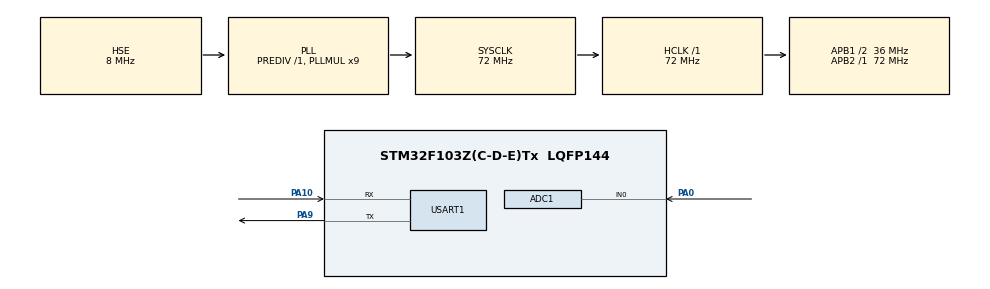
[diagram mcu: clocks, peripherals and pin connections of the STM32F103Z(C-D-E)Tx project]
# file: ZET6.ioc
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ADC1.Channel-0\#ChannelRegularConversion=ADC_CHANNEL_0
ADC1.ContinuousConvMode=DISABLE
ADC1.NbrOfConversionFlag=1
ADC1.Rank-0\#ChannelRegularConversion=1
ADC1.SamplingTime-0\#ChannelRegularConversion=ADC_SAMPLETIME_239CYCLES_5
ADC1.master=1
Mcu.Family=STM32F1
Mcu.Name=STM32F103Z(C-D-E)Tx
Mcu.Package=LQFP144
NVIC.PriorityGroup=NVIC_PRIORITYGROUP_4
OSC_IN.Mode=HSE-External-Oscillator
OSC_IN.Signal=RCC_OSC_IN
OSC_OUT.Mode=HSE-External-Oscillator
OSC_OUT.Signal=RCC_OSC_OUT
PA0-WKUP.Signal=ADCx_IN0
PA10.Mode=Asynchronous
PA10.Signal=USART1_RX
PA13.Signal=SYS_JTMS-SWDIO
PA14.Signal=SYS_JTCK-SWCLK
PA9.Mode=Asynchronous
PA9.Signal=USART1_TX
ProjectManager.HeapSize=0x200
ProjectManager.StackSize=0x400
ProjectManager.TargetToolchain=MDK-ARM V5.27
RCC.ADCPresc=RCC_ADCPCLK2_DIV8
RCC.AHBFreq_Value=72000000
RCC.APB1CLKDivider=RCC_HCLK_DIV2
RCC.APB1Freq_Value=36000000
RCC.APB1TimFreq_Value=72000000
RCC.APB2Freq_Value=72000000
RCC.APB2TimFreq_Value=72000000
RCC.HCLKFreq_Value=72000000
RCC.PLLMUL=RCC_PLL_MUL9
RCC.PLLSourceVirtual=RCC_PLLSOURCE_HSE
RCC.SYSCLKFreq_VALUE=72000000
RCC.SYSCLKSource=RCC_SYSCLKSOURCE_PLLCLK
RCC.USBFreq_Value=72000000
SH.ADCx_IN0.0=ADC1_IN0,IN0
USART1.VirtualMode=VM_ASYNC
VP_SYS_VS_ND.Mode=No_Debug
board=custom

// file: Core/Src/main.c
/* USER CODE BEGIN Header */
/**
  ******************************************************************************
  * @file           : main.c
  * @brief          : Main program body
  ******************************************************************************
  * @attention
  *
  * <h2><center>&copy; Copyright (c) 2021 STMicroelectronics.
  * All rights reserved.</center></h2>
  *
  * This software component is licensed by ST under BSD 3-Clause license,
  * the "License"; You may not use this file except in compliance with the
  * License. You may obtain a copy of the License at:
  *                        opensource.org/licenses/BSD-3-Clause
  *
  ******************************************************************************
  */
/* USER CODE END Header */
#include "main.h"
#include "debug.h"

ADC_HandleTypeDef hadc1;

UART_HandleTypeDef huart1;

void SystemClock_Config(void);
static void MX_GPIO_Init(void);
static void MX_ADC1_Init(void);
static void MX_USART1_UART_Init(void);

/* USER CODE BEGIN 0 */

uint16_t Get_Adc1_val()               //ADC获取
{
    HAL_ADC_Start(&hadc1);

    HAL_ADC_PollForConversion(&hadc1, 100);

    if(HAL_IS_BIT_SET(HAL_ADC_GetState(&hadc1), HAL_ADC_STATE_REG_EOC))
    {
        return HAL_ADC_GetValue(&hadc1);
    }
    return 0;
}

uint16_t Get_Adc1_Average()          //50ms数据融合
{
	uint8_t i,j = 0;
	uint16_t buf[10];
	uint16_t tempval = 0;

	for(i=0;i<10;i++)
	{
		buf[i] = Get_Adc1_val();
		HAL_Delay(5);
	}

	for(i=0;i<9;i++)                 //冒泡排序
	{
		for(j=0;j<9-i;j++)
		{
			if(buf[j]>buf[j+1])
			{
				tempval = buf[j];
				buf[j] = buf[j+1];
				buf[j+1] = tempval;
			}
		}
	}

	tempval = 0;
	for(i=1;i<9;i++)
	{
		tempval += buf[i];
	}

	return tempval/8;
}

uint16_t Get_Array_Max(uint16_t *data,uint8_t num)
{
	int max = 0;
	int i = 0;

	for(i=0;i<num;i++)
	{
		if(max < data[i])
		{
			max = data[i];
		}
	}

	return max;
}

uint16_t Get_Array_Min(uint16_t *data,uint8_t num)
{
	int min = 999;
	int i = 0;

	for(i=0;i<num;i++)
	{
		if(min > data[i])
		{
			min = data[i];
		}
	}

	return min;
}

/* USER CODE END 0 */

int main(void)
{
    /* USER CODE BEGIN 1 */

    uint16_t adcval,count = 0;
	uint16_t temp,max,min,mid,stateindex = 0;
	uint16_t time1,time2,BPM = 0;
	uint16_t data[50] = {0};

	uint16_t preReadData,readData = 0;
	uint16_t filter = 200;
	uint8_t index = 0;

	uint8_t Pre_State,Now_State = 0;

    /* USER CODE END 1 */

    /* MCU Configuration--------------------------------------------------------*/

    /* Reset of all peripherals, Initializes the Flash interface and the Systick. */
    HAL_Init();

    /* Configure the system clock */
    SystemClock_Config();

    /* Initialize all configured peripherals */
    MX_GPIO_Init();
    MX_ADC1_Init();
    MX_USART1_UART_Init();

    /* Infinite loop */
    /* USER CODE BEGIN WHILE */
    while(1)
    {

		preReadData = readData;
		temp = Get_Adc1_Average()-1500;
		if(temp < 1000)
		{
			readData = temp;
		}
//		if((readData-preReadData) < filter)    //滤除突变噪声信号
//		{
			data[index++] = readData;
//		}

		if(index >= 20)
		{
			index = 0;

			max = Get_Array_Max(data,20);
			min = Get_Array_Min(data,20);
			mid = max-3;
			filter = (max-min)/2;
		}

		Pre_State = Now_State;

		Now_State = (readData>mid)?1:0;

		if((Pre_State == 0)&&(Now_State == 1))
		{
			stateindex++;
			stateindex %= 2;

			if(stateindex == 1)
			{
				time1 = HAL_GetTick();
			}
			if(stateindex == 0)
			{
				time2 = HAL_GetTick();
				BPM = 60000/(time2-time1);
				printf("BPM:%d\r\n",BPM);
			}
		}

//		HAL_Delay(20);
		count++;
		printf("A%d\r\n",readData);

        /* USER CODE END WHILE */

    }
}

void SystemClock_Config(void)
{
    RCC_OscInitTypeDef RCC_OscInitStruct = {0};
    RCC_ClkInitTypeDef RCC_ClkInitStruct = {0};
    RCC_PeriphCLKInitTypeDef PeriphClkInit = {0};

    /** Initializes the RCC Oscillators according to the specified parameters
    * in the RCC_OscInitTypeDef structure.
    */
    RCC_OscInitStruct.OscillatorType = RCC_OSCILLATORTYPE_HSE;
    RCC_OscInitStruct.HSEState = RCC_HSE_ON;
    RCC_OscInitStruct.HSEPredivValue = RCC_HSE_PREDIV_DIV1;
    RCC_OscInitStruct.HSIState = RCC_HSI_ON;
    RCC_OscInitStruct.PLL.PLLState = RCC_PLL_ON;
    RCC_OscInitStruct.PLL.PLLSource = RCC_PLLSOURCE_HSE;
    RCC_OscInitStruct.PLL.PLLMUL = RCC_PLL_MUL9;
    if(HAL_RCC_OscConfig(&RCC_OscInitStruct) != HAL_OK)
    {
        Error_Handler();
    }
    /** Initializes the CPU, AHB and APB buses clocks
    */
    RCC_ClkInitStruct.ClockType = RCC_CLOCKTYPE_HCLK | RCC_CLOCKTYPE_SYSCLK
                                  | RCC_CLOCKTYPE_PCLK1 | RCC_CLOCKTYPE_PCLK2;
    RCC_ClkInitStruct.SYSCLKSource = RCC_SYSCLKSOURCE_PLLCLK;
    RCC_ClkInitStruct.AHBCLKDivider = RCC_SYSCLK_DIV1;
    RCC_ClkInitStruct.APB1CLKDivider = RCC_HCLK_DIV2;
    RCC_ClkInitStruct.APB2CLKDivider = RCC_HCLK_DIV1;

    if(HAL_RCC_ClockConfig(&RCC_ClkInitStruct, FLASH_LATENCY_2) != HAL_OK)
    {
        Error_Handler();
    }
    PeriphClkInit.PeriphClockSelection = RCC_PERIPHCLK_ADC;
    PeriphClkInit.AdcClockSelection = RCC_ADCPCLK2_DIV8;
    if(HAL_RCCEx_PeriphCLKConfig(&PeriphClkInit) != HAL_OK)
    {
        Error_Handler();
    }
}

static void MX_ADC1_Init(void)
{

    ADC_ChannelConfTypeDef sConfig = {0};

    /** Common config
    */
    hadc1.Instance = ADC1;
    hadc1.Init.ScanConvMode = ADC_SCAN_DISABLE;
    hadc1.Init.ContinuousConvMode = DISABLE;
    hadc1.Init.DiscontinuousConvMode = DISABLE;
    hadc1.Init.ExternalTrigConv = ADC_SOFTWARE_START;
    hadc1.Init.DataAlign = ADC_DATAALIGN_RIGHT;
    hadc1.Init.NbrOfConversion = 1;
    if(HAL_ADC_Init(&hadc1) != HAL_OK)
    {
        Error_Handler();
    }
    /** Configure Regular Channel
    */
    sConfig.Channel = ADC_CHANNEL_0;
    sConfig.Rank = ADC_REGULAR_RANK_1;
    sConfig.SamplingTime = ADC_SAMPLETIME_239CYCLES_5;
    if(HAL_ADC_ConfigChannel(&hadc1, &sConfig) != HAL_OK)
    {
        Error_Handler();
    }

}

static void MX_USART1_UART_Init(void)
{

    huart1.Instance = USART1;
    huart1.Init.BaudRate = 115200;
    huart1.Init.WordLength = UART_WORDLENGTH_8B;
    huart1.Init.StopBits = UART_STOPBITS_1;
    huart1.Init.Parity = UART_PARITY_NONE;
    huart1.Init.Mode = UART_MODE_TX_RX;
    huart1.Init.HwFlowCtl = UART_HWCONTROL_NONE;
    huart1.Init.OverSampling = UART_OVERSAMPLING_16;
    if(HAL_UART_Init(&huart1) != HAL_OK)
    {
        Error_Handler();
    }

}

static void MX_GPIO_Init(void)
{

    /* GPIO Ports Clock Enable */
    __HAL_RCC_GPIOA_CLK_ENABLE();

}

void Error_Handler(void)
{
    __disable_irq();
    while(1)
    {
    }
}

/************************ (C) COPYRIGHT STMicroelectronics *****END OF FILE****/
